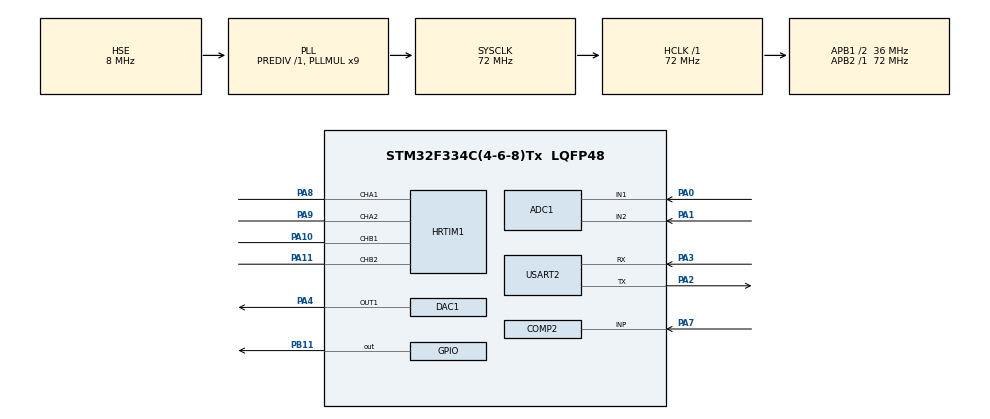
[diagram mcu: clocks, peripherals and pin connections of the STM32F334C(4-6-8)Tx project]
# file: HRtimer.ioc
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ADC1.Channel-0\#ChannelRegularConversion=ADC_CHANNEL_1
ADC1.ContinuousConvMode=ENABLE
ADC1.NbrOfConversion=1
ADC1.NbrOfConversionFlag=1
ADC1.Offset-0\#ChannelRegularConversion=0
ADC1.OffsetNumber-0\#ChannelRegularConversion=ADC_OFFSET_NONE
ADC1.Rank-0\#ChannelRegularConversion=1
ADC1.SamplingTime-0\#ChannelRegularConversion=ADC_SAMPLETIME_1CYCLE_5
ADC1.SingleDiff-0\#ChannelRegularConversion=ADC_DIFFERENTIAL_ENDED
ADC1.master=1
COMP2.InvertingInput=COMP_INVERTINGINPUT_DAC1_CH1
COMP2.TriggerMode=COMP_TRIGGERMODE_IT_RISING_FALLING
HRTIM1.CompareUnit1-Output_TA1TA2=HRTIM_COMPAREUNIT_1
HRTIM1.CompareUnit2-Output_TA1TA2=__NULL
HRTIM1.CompareValue1-Output_TA1TA2=0x60
HRTIM1.DeadTimeInsertion-Output_TA1TA2=HRTIM_TIMDEADTIMEINSERTION_DISABLED
HRTIM1.Deadtimeconfig-Output_TA1TA2=HRTIM_TIMERINDEX_TIMER_A
HRTIM1.Deadtimeconfig-Output_TB1TB2=HRTIM_TIMERINDEX_TIMER_B
HRTIM1.HRTIMInterruptResquests1=HRTIM_IT_NONE
HRTIM1.Periode_TA=0x2a7
HRTIM1.Periode_TB=0x2a7
HRTIM1.Periode_TC=0x153
HRTIM1.Polarity2-Output_TA1TA2=HRTIM_OUTPUTPOLARITY_LOW
HRTIM1.Polarity2-Output_TB1TB2=HRTIM_OUTPUTPOLARITY_LOW
HRTIM1.PreloadEnable-Output_TA1TA2=HRTIM_PRELOAD_ENABLED
HRTIM1.PrescalerDead-Output_TA1TA2=HRTIM_TIMDEADTIME_PRESCALERRATIO_DIV1
HRTIM1.PrescalerRatio_TA=HRTIM_PRESCALERRATIO_MUL32
HRTIM1.RepetitionUpdate-Output_TA1TA2=HRTIM_UPDATEONREPETITION_ENABLED
Mcu.Family=STM32F3
Mcu.Name=STM32F334C(4-6-8)Tx
Mcu.Package=LQFP48
NVIC.COMP2_IRQn=true\:0\:0\:false\:false\:true
NVIC.HRTIM1_TIMA_IRQn=true\:0\:0\:false\:false\:true
NVIC.HRTIM1_TIMC_IRQn=true\:0\:0\:false\:false\:true
NVIC.PriorityGroup=NVIC_PRIORITYGROUP_4
PA0.Mode=IN1-Differential
PA0.Signal=ADC1_IN1
PA1.Mode=IN1-Differential
PA1.Signal=ADC1_IN2
PA10.Mode=Output_TB1TB2
PA10.Signal=HRTIM1_CHB1
PA11.Mode=Output_TB1TB2
PA11.Signal=HRTIM1_CHB2
PA13.Mode=Serial_Wire
PA13.Signal=SYS_JTMS-SWDIO
PA14.Mode=Serial_Wire
PA14.Signal=SYS_JTCK-SWCLK
PA2.Mode=Asynchronous
PA2.Signal=USART2_TX
PA3.Mode=Asynchronous
PA3.Signal=USART2_RX
PA4.Signal=COMP_DAC11_group
PA7.Mode=INP
PA7.Signal=COMP2_INP
PA8.Mode=Output_TA1TA2
PA8.Signal=HRTIM1_CHA1
PA9.Mode=Output_TA1TA2
PA9.Signal=HRTIM1_CHA2
PB11.Signal=GPIO_Output
PF0\ /\ OSC_IN.Mode=HSE-External-Oscillator
PF0\ /\ OSC_IN.Signal=RCC_OSC_IN
PF1\ /\ OSC_OUT.Mode=HSE-External-Oscillator
PF1\ /\ OSC_OUT.Signal=RCC_OSC_OUT
ProjectManager.HeapSize=0x200
ProjectManager.StackSize=0x400
ProjectManager.TargetToolchain=MDK-ARM V5
RCC.AHBFreq_Value=72000000
RCC.APB1CLKDivider=RCC_HCLK_DIV2
RCC.APB1Freq_Value=36000000
RCC.APB1TimFreq_Value=72000000
RCC.APB2Freq_Value=72000000
RCC.APB2TimFreq_Value=72000000
RCC.CortexFreq_Value=72000000
RCC.HCLKFreq_Value=72000000
RCC.HRTIMSelection=RCC_HRTIM1CLK_PLLCLK
RCC.HSE_VALUE=8000000
RCC.HSIState=RCC_HSI_ON
RCC.HSI_VALUE=8000000
RCC.LSE_VALUE=32768
RCC.PLLMUL=RCC_PLL_MUL9
RCC.PLLSourceVirtual=RCC_PLLSOURCE_HSE
RCC.SYSCLKFreq_VALUE=72000000
RCC.SYSCLKSourceVirtual=RCC_SYSCLKSOURCE_PLLCLK
SH.COMP_DAC11_group.0=DAC1_OUT1,DAC_OUT1
VP_COMP2_VS_DAC1OUT1.Mode=INM_DAC1OUT1
VP_HRTIM1_VS_hrtimTimerCNoOutput.Mode=No_output_TC
board=HRtimer

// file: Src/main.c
/**
  ******************************************************************************
  * File Name          : main.c
  * Description        : Main program body
  ******************************************************************************
  *
  * COPYRIGHT(c) 2017 STMicroelectronics
  *
  * Redistribution and use in source and binary forms, with or without modification,
  * are permitted provided that the following conditions are met:
  *   1. Redistributions of source code must retain the above copyright notice,
  *      this list of conditions and the following disclaimer.
  *   2. Redistributions in binary form must reproduce the above copyright notice,
  *      this list of conditions and the following disclaimer in the documentation
  *      and/or other materials provided with the distribution.
  *   3. Neither the name of STMicroelectronics nor the names of its contributors
  *      may be used to endorse or promote products derived from this software
  *      without specific prior written permission.
  *
  * THIS SOFTWARE IS PROVIDED BY THE COPYRIGHT HOLDERS AND CONTRIBUTORS "AS IS"
  * AND ANY EXPRESS OR IMPLIED WARRANTIES, INCLUDING, BUT NOT LIMITED TO, THE
  * IMPLIED WARRANTIES OF MERCHANTABILITY AND FITNESS FOR A PARTICULAR PURPOSE ARE
  * DISCLAIMED. IN NO EVENT SHALL THE COPYRIGHT HOLDER OR CONTRIBUTORS BE LIABLE
  * FOR ANY DIRECT, INDIRECT, INCIDENTAL, SPECIAL, EXEMPLARY, OR CONSEQUENTIAL
  * DAMAGES (INCLUDING, BUT NOT LIMITED TO, PROCUREMENT OF SUBSTITUTE GOODS OR
  * SERVICES; LOSS OF USE, DATA, OR PROFITS; OR BUSINESS INTERRUPTION) HOWEVER
  * CAUSED AND ON ANY THEORY OF LIABILITY, WHETHER IN CONTRACT, STRICT LIABILITY,
  * OR TORT (INCLUDING NEGLIGENCE OR OTHERWISE) ARISING IN ANY WAY OUT OF THE USE
  * OF THIS SOFTWARE, EVEN IF ADVISED OF THE POSSIBILITY OF SUCH DAMAGE.
  *
  ******************************************************************************
  */
#include "main.h"
#include "stm32f3xx_hal.h"
#include "adc.h"
#include "comp.h"
#include "dac.h"
#include "hrtim.h"
#include "usart.h"
#include "gpio.h"

#include "utils.h"

/* USER CODE BEGIN PV */
/* Private variables ---------------------------------------------------------*/

/* USER CODE END PV */

void SystemClock_Config(void);
void Error_Handler(void);

/* USER CODE BEGIN PFP */
/* Private function prototypes -----------------------------------------------*/

/* USER CODE END PFP */

int main(void)
{

  /* MCU Configuration----------------------------------------------------------*/

  /* Reset of all peripherals, Initializes the Flash interface and the Systick. */
  HAL_Init();

  /* Configure the system clock */
  SystemClock_Config();

  /* Initialize all configured peripherals */
  MX_GPIO_Init();
  MX_ADC1_Init();
  MX_COMP2_Init();
  MX_DAC1_Init();
  MX_HRTIM1_Init();
  MX_USART2_UART_Init();

	////HAL_HRTIM_WaveformSetOutputLevel(&hhrtim1, HRTIM_TIMERINDEX_TIMER_A, HRTIM_OUTPUT_TA1, HRTIM_OUTPUTLEVEL_ACTIVE);
	HAL_HRTIM_WaveformOutputStart(&hhrtim1, HRTIM_OUTPUT_TA1 | HRTIM_OUTPUT_TA2 | HRTIM_OUTPUT_TB1 | HRTIM_OUTPUT_TB2);
	//HAL_HRTIM_WaveformCounterStart_IT(&hhrtim1, HRTIM_TIMERID_TIMER_A);
	HAL_HRTIM_WaveformCounterStart(&hhrtim1, HRTIM_TIMERID_TIMER_A | HRTIM_TIMERID_TIMER_B);

	advanced_int_init();
	update_phase(20000);

	//enable repetition interrupt
	//__HAL_HRTIM_TIMER_ENABLE_IT(&hhrtim1, HRTIM_TIMERINDEX_TIMER_A, HRTIM_TIM_IT_REP);

	//HAL_HRTIM_SimpleBaseStart(&hhrtim1,HRTIM_TIMERINDEX_TIMER_A);
	////HAL_HRTIM_SimpleBaseStart_IT(&hhrtim1,HRTIM_TIMERINDEX_TIMER_A);

	//HAL_HRTIM_SimplePWMStart(&hhrtim1,HRTIM_TIMERINDEX_TIMER_A, HRTIM_OUTPUT_TA1);
	//HAL_HRTIM_SimplePWMStart(&hhrtim1,HRTIM_TIMERINDEX_TIMER_A, HRTIM_OUTPUT_TA2);

  /* Infinite loop */
  /* USER CODE BEGIN WHILE */
	uint16_t v = 20000; //max 65500
	uint8_t x = 0;
  while (1)
  {
  /* USER CODE END WHILE */
		if(x)
			update_phase(v);
		HAL_Delay(500);
		x = 0;
  }

}

/** System Clock Configuration
*/

void HAL_HRTIM_RepetitionEventCallback(HRTIM_HandleTypeDef * hhrtim, uint32_t TimerIdx)
{

	//uint32_t x = HAL_HRTIM_WaveformGetOutputState(&hhrtim1,HRTIM_TIMERINDEX_TIMER_A, HRTIM_OUTPUT_TA1);
	HAL_GPIO_TogglePin(GPIOB, GPIO_PIN_11);
  UNUSED(hhrtim);
  UNUSED(TimerIdx);

}

void SystemClock_Config(void)
{

  RCC_OscInitTypeDef RCC_OscInitStruct;
  RCC_ClkInitTypeDef RCC_ClkInitStruct;
  RCC_PeriphCLKInitTypeDef PeriphClkInit;

    /**Initializes the CPU, AHB and APB busses clocks
    */
  RCC_OscInitStruct.OscillatorType = RCC_OSCILLATORTYPE_HSE;
  RCC_OscInitStruct.HSEState = RCC_HSE_ON;
  RCC_OscInitStruct.HSEPredivValue = RCC_HSE_PREDIV_DIV1;
  RCC_OscInitStruct.HSIState = RCC_HSI_ON;
  RCC_OscInitStruct.PLL.PLLState = RCC_PLL_ON;
  RCC_OscInitStruct.PLL.PLLSource = RCC_PLLSOURCE_HSE;
  RCC_OscInitStruct.PLL.PLLMUL = RCC_PLL_MUL9;
  if (HAL_RCC_OscConfig(&RCC_OscInitStruct) != HAL_OK)
  {
    Error_Handler();
  }

    /**Initializes the CPU, AHB and APB busses clocks
    */
  RCC_ClkInitStruct.ClockType = RCC_CLOCKTYPE_HCLK|RCC_CLOCKTYPE_SYSCLK
                              |RCC_CLOCKTYPE_PCLK1|RCC_CLOCKTYPE_PCLK2;
  RCC_ClkInitStruct.SYSCLKSource = RCC_SYSCLKSOURCE_PLLCLK;
  RCC_ClkInitStruct.AHBCLKDivider = RCC_SYSCLK_DIV1;
  RCC_ClkInitStruct.APB1CLKDivider = RCC_HCLK_DIV2;
  RCC_ClkInitStruct.APB2CLKDivider = RCC_HCLK_DIV1;

  if (HAL_RCC_ClockConfig(&RCC_ClkInitStruct, FLASH_LATENCY_2) != HAL_OK)
  {
    Error_Handler();
  }

  PeriphClkInit.PeriphClockSelection = RCC_PERIPHCLK_HRTIM1|RCC_PERIPHCLK_ADC12;
  PeriphClkInit.Adc12ClockSelection = RCC_ADC12PLLCLK_DIV1;
  PeriphClkInit.Hrtim1ClockSelection = RCC_HRTIM1CLK_PLLCLK;
  if (HAL_RCCEx_PeriphCLKConfig(&PeriphClkInit) != HAL_OK)
  {
    Error_Handler();
  }

    /**Configure the Systick interrupt time
    */
  HAL_SYSTICK_Config(HAL_RCC_GetHCLKFreq()/1000);

    /**Configure the Systick
    */
  HAL_SYSTICK_CLKSourceConfig(SYSTICK_CLKSOURCE_HCLK);

  /* SysTick_IRQn interrupt configuration */
  HAL_NVIC_SetPriority(SysTick_IRQn, 0, 0);
}

void Error_Handler(void)
{
  while(1)
  {
  }
}

/************************ (C) COPYRIGHT STMicroelectronics *****END OF FILE****/
